# S32M24x register map
Vendor: NXP Semiconductors; File version: 1.5
CPU: CM4 r0p1, little endian, MPU, FPU, VTOR, 4 interrupt priority bits
Registers are 32-bit, read-write, reset 0x0 unless marked. A register's access mark holds for its fields unless they carry their own. Offsets are from the block's base; [hi:lo] are bit positions; {n}, {i} and the like mark numbered series.

## SMC
Base 0x4007E000
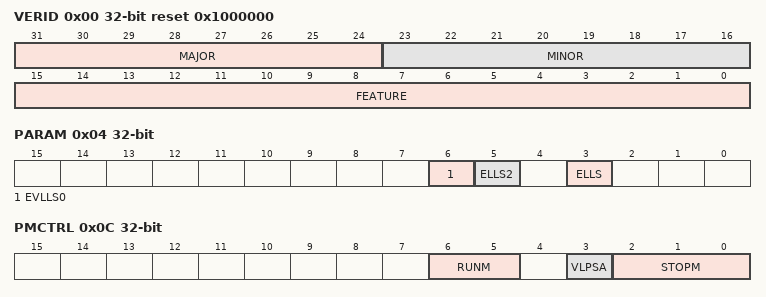
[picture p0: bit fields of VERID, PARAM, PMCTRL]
0x00 VERID ro reset 0x1000000 — SMC Version ID Register
  [31:24] MAJOR — Major Version Number
  [23:16] MINOR — Minor Version Number
  [15:0] FEATURE — Feature Specification Number
    0=Standard features implemented
0x04 PARAM ro — SMC Parameter Register
  [all] fields
    0=The feature is not available; 1=The feature is available
  [6] EVLLS0 — Existence of VLLS0 feature
  [5] ELLS2 — Existence of LLS2 feature
  [3] ELLS — Existence of LLS feature
0x08 PMPROT (reset mask 0xFFFFFFDF) — Power Mode Protection register
  [5] AVLP — Allow Very-Low-Power Modes
    0=VLPR and VLPS are not allowed; 1=VLPR and VLPS are allowed
0x0C PMCTRL (reset mask 0xFFFFFF9F) — Power Mode Control register
  [6:5] RUNM — Run Mode Control
    0=Normal Run mode (RUN); 2=Very-Low-Power Run mode (VLPR)
  [3] VLPSA ro — Very Low Power Stop Aborted
    0=The previous stop mode entry was successful; 1=The previous stop mode entry was aborted
  [2:0] STOPM — Stop Mode Control
    0=Normal Stop (STOP); 2=Very-Low-Power Stop (VLPS)
0x10 STOPCTRL reset 0x3 — Stop Control Register
  [7:6] STOPO — Stop Option
    1=STOP1 - Stop with both system and bus clocks disabled; 2=STOP2 - Stop with system clock disabled and bus clock enabled
0x14 PMSTAT ro (reset mask 0xFFFFFF00) — Power Mode Status register
  [7:0] PMSTAT — Power Mode Status
    1=Current power mode is RUN; 4=Current power mode is VLPR; 16=Current power mode is VLPS

## PTA — GPIO
Base 0x400FF000
Same registers: PTB 0x400FF040, PTC 0x400FF080, PTD 0x400FF0C0, PTE 0x400FF100
0x00 PDOR — Port Data Output Register
  [31:0] PDO — Port Data Output
0x04 PSOR — Port Set Output Register
  [31:0] PTSO — Port Set Output
0x08 PCOR — Port Clear Output Register
  [31:0] PTCO — Port Clear Output
0x0C PTOR — Port Toggle Output Register
  [31:0] PTTO — Port Toggle Output
0x10 PDIR ro — Port Data Input Register
  [31:0] PDI — Port Data Input
0x14 PDDR — Port Data Direction Register
  [31:0] PDD — Port Data Direction
0x18 PIDR — Port Input Disable Register
  [31:0] PID — Port Input Disable

## LMEM
Base 0xE0082000
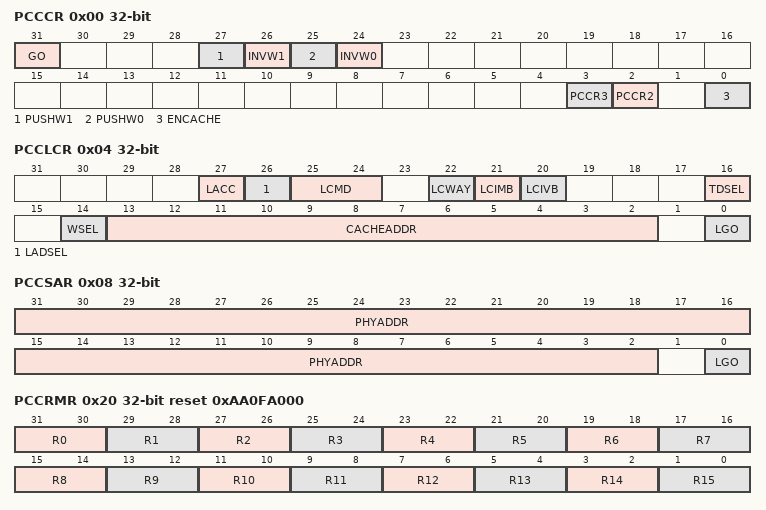
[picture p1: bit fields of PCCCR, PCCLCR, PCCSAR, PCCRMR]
0x00 PCCCR — Cache control register
  [31] GO — Initiate Cache Command
    0=Write: no effect. Read: no cache command active.; 1=Write: initiate command indicated by bits 27-24. Read: cache command active.
  [27] PUSHW1 — Push Way 1
    0=No operation; 1=When setting the GO bit, push all modified lines in way 1
  [26] INVW1 — Invalidate Way 1
    0=No operation; 1=When setting the GO bit, invalidate all lines in way 1
  [25] PUSHW0 — Push Way 0
    0=No operation; 1=When setting the GO bit, push all modified lines in way 0
  [24] INVW0 — Invalidate Way 0
    0=No operation; 1=When setting the GO bit, invalidate all lines in way 0
  [3] PCCR3 — Forces no allocation on cache misses
    0=Allocation on cache misses; 1=Forces no allocation on cache misses (must also have PCCR2 asserted)
  [2] PCCR2 — Forces all cacheable spaces to write through
    0=Does NOT force all cacheable spaces to write through; 1=Forces all cacheable spaces to write through
  [0] ENCACHE — Cache enable
    0=Cache disabled; 1=Cache enabled
0x04 PCCLCR — Cache line control register
  [27] LACC — Line access type
    0=Read; 1=Write
  [26] LADSEL — Line Address Select
    0=Cache address; 1=Physical address
  [25:24] LCMD — Line Command
    0=Search and read or write; 1=Invalidate; 2=Push; 3=Clear
  [22] LCWAY — Line Command Way
  [21] LCIMB — Line Command Initial Modified Bit
  [20] LCIVB — Line Command Initial Valid Bit
  [16] TDSEL — Tag/Data Select
    0=Data; 1=Tag
  [14] WSEL — Way select
    0=Way 0; 1=Way 1
  [13:2] CACHEADDR — Cache address
  [0] LGO — Initiate Cache Line Command
    0=Write: no effect. Read: no line command active.; 1=Write: initiate line command indicated by bits 27-24. Read: line command active.
0x08 PCCSAR — Cache search address register
  [31:2] PHYADDR — Physical Address
  [0] LGO — Initiate Cache Line Command
    0=Write: no effect. Read: no line command active.; 1=Write: initiate line command indicated by bits CLCR[27:24]. Read: line command active.
0x0C PCCCVR — Cache read/write value register
  [31:0] DATA — Cache read/write Data
0x20 PCCRMR reset 0xAA0FA000 — Cache regions mode register
  [all] fields
    0=Non-cacheable; 1=Non-cacheable; 2=Write-through; 3=Write-back
  [31-2n:30-2n] R{n} (n=0..15) — Region {n} mode
